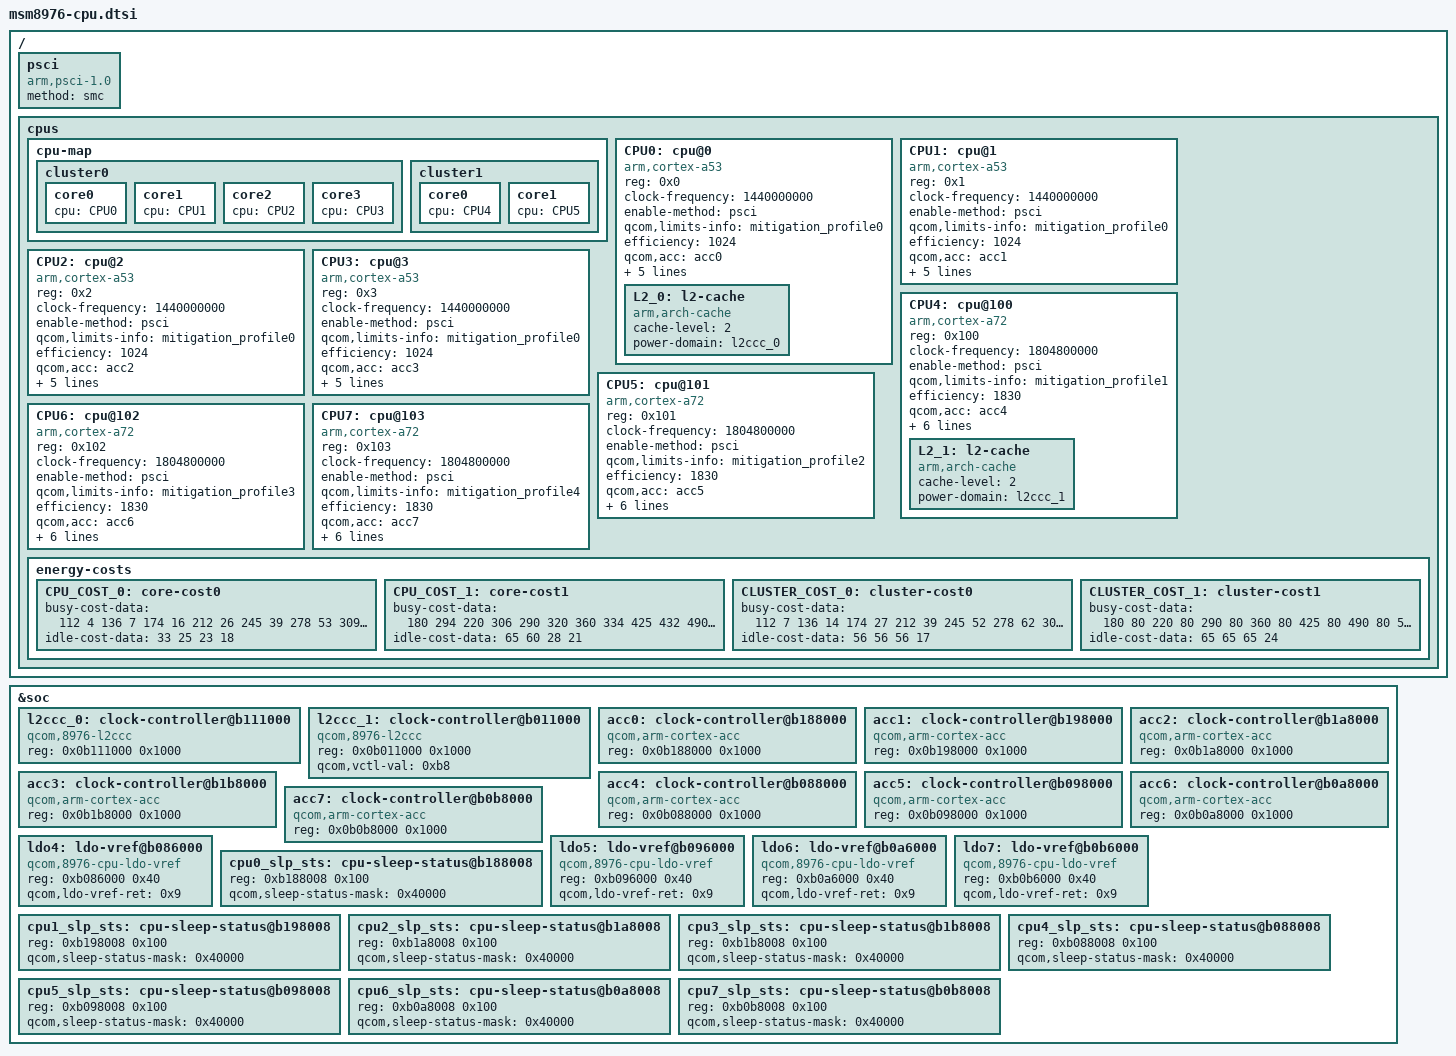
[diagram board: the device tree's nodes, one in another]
/* Copyright (c) 2015, The Linux Foundation. All rights reserved.
 *
 * This program is free software; you can redistribute it and/or modify
 * it under the terms of the GNU General Public License version 2 and
 * only version 2 as published by the Free Software Foundation.
 *
 * This program is distributed in the hope that it will be useful,
 * but WITHOUT ANY WARRANTY; without even the implied warranty of
 * MERCHANTABILITY or FITNESS FOR A PARTICULAR PURPOSE.  See the
 * GNU General Public License for more details.
 */


/ {

	psci {
		compatible = "arm,psci-1.0";
		method = "smc";
	};

	cpus {
		#address-cells = <1>;
		#size-cells = <0>;
		cpu-map {
			cluster0 {
				core0 {
					cpu = <&CPU0>;
				};
				core1 {
					cpu = <&CPU1>;
				};
				core2 {
					cpu = <&CPU2>;
				};
				core3 {
					cpu = <&CPU3>;
				};
			};

			cluster1 {
				core0 {
					cpu = <&CPU4>;
				};
				core1 {
					cpu = <&CPU5>;
				};
			};
		};

		CPU0: cpu@0 {
			device_type = "cpu";
			compatible = "arm,cortex-a53","arm,armv8";
			reg = <0x0>;
			clock-frequency = <1440000000>;
			enable-method = "psci";
			qcom,limits-info = <&mitigation_profile0>;
			efficiency = <1024>;
			qcom,acc = <&acc0>;
			next-level-cache = <&L2_0>;
			sched-energy-costs = <&CPU_COST_0 &CLUSTER_COST_0>;
			// The currents(uA) correspond to the frequencies in the
			// frequency table.
			current = < 18250 // 	 400000 kHZ
			            24330 // 	 691200 kHZ
			            26920 // 	 806400 kHZ
			            34600 //	1017600 kHz
			            38150 //	1190400 kHZ
			            46880 //	1305600 kHZ
			            55940 //	1382400 kHZ
			            81740 //	1401600 kHZ
			            105870>; //	1440000 kHZ
			qcom,sleep-status = <&cpu0_slp_sts>;
			L2_0: l2-cache {
			      compatible = "arm,arch-cache";
			      cache-level = <2>;
			      power-domain = <&l2ccc_0>;
			};
		};

		CPU1: cpu@1 {
			device_type = "cpu";
			compatible = "arm,cortex-a53","arm,armv8";
			reg = <0x1>;
			clock-frequency = <1440000000>;
			enable-method = "psci";
			qcom,limits-info = <&mitigation_profile0>;
			efficiency = <1024>;
			qcom,acc = <&acc1>;
			next-level-cache = <&L2_0>;
			sched-energy-costs = <&CPU_COST_0 &CLUSTER_COST_0>;
			// The currents(uA) correspond to the frequencies in the
			// frequency table.
			current = < 18250 // 	 400000 kHZ
			            24330 // 	 691200 kHZ
			            26920 // 	 806400 kHZ
			            34600 //	1017600 kHz
			            38150 //	1190400 kHZ
			            46880 //	1305600 kHZ
			            55940 //	1382400 kHZ
			            81740 //	1401600 kHZ
			            105870>; //	1440000 kHZ
			qcom,sleep-status = <&cpu1_slp_sts>;
		};

		CPU2: cpu@2 {
			device_type = "cpu";
			compatible = "arm,cortex-a53","arm,armv8";
			reg = <0x2>;
			clock-frequency = <1440000000>;
			enable-method = "psci";
			qcom,limits-info = <&mitigation_profile0>;
			efficiency = <1024>;
			qcom,acc = <&acc2>;
			next-level-cache = <&L2_0>;
			sched-energy-costs = <&CPU_COST_0 &CLUSTER_COST_0>;
			// The currents(uA) correspond to the frequencies in the
			// frequency table.
			current = < 18250 // 	 400000 kHZ
			            24330 // 	 691200 kHZ
			            26920 // 	 806400 kHZ
			            34600 //	1017600 kHz
			            38150 //	1190400 kHZ
			            46880 //	1305600 kHZ
			            55940 //	1382400 kHZ
			            81740 //	1401600 kHZ
			            105870>; //	1440000 kHZ
			qcom,sleep-status = <&cpu2_slp_sts>;
		};

		CPU3: cpu@3 {
			device_type = "cpu";
			compatible = "arm,cortex-a53","arm,armv8";
			reg = <0x3>;
			clock-frequency = <1440000000>;
			enable-method = "psci";
			qcom,limits-info = <&mitigation_profile0>;
			efficiency = <1024>;
			qcom,acc = <&acc3>;
			next-level-cache = <&L2_0>;
			sched-energy-costs = <&CPU_COST_0 &CLUSTER_COST_0>;
			// The currents(uA) correspond to the frequencies in the
			// frequency table.
			current = < 18250 // 	 400000 kHZ
			            24330 // 	 691200 kHZ
			            26920 // 	 806400 kHZ
			            34600 //	1017600 kHz
			            38150 //	1190400 kHZ
			            46880 //	1305600 kHZ
			            55940 //	1382400 kHZ
			            81740 //	1401600 kHZ
			            105870>; //	1440000 kHZ
			qcom,sleep-status = <&cpu3_slp_sts>;
		};

		CPU4: cpu@100 {
			device_type = "cpu";
			compatible = "arm,cortex-a72","arm,armv8";
			reg = <0x100>;
			clock-frequency = <1804800000>;
			enable-method = "psci";
			qcom,limits-info = <&mitigation_profile1>;
			efficiency = <1830>;
			qcom,acc = <&acc4>;
			qcom,ldo = <&ldo4>;
			next-level-cache = <&L2_1>;
			sched-energy-costs = <&CPU_COST_1 &CLUSTER_COST_1>;
			// The currents(uA) correspond to the frequencies in the
			// frequency table.
			current = < 67740 // 	 400000 kHZ
			            82960 // 	 883200 kHZ
			            105870 // 	 940800 kHZ
			            133160 // 	 998400 kHZ
			            150160 //	1056000 kHZ
			            167180 //	1113600 kHZ
			            230040 //	1190400 kHZ
			            261430 //	1248000 kHZ
			            290460 //	1305600 kHZ
			            317200 //	1382400 kHZ
			            352870 //	1612800 kHZ
			            374360 //	1747200 kHZ
			            443880>; //	1804800 kHZ
			qcom,sleep-status = <&cpu4_slp_sts>;
			L2_1: l2-cache {
			      compatible = "arm,arch-cache";
			      cache-level = <2>;
			      power-domain = <&l2ccc_1>;
			};
		};

		CPU5: cpu@101 {
			device_type = "cpu";
			compatible = "arm,cortex-a72","arm,armv8";
			reg = <0x101>;
			clock-frequency = <1804800000>;
			enable-method = "psci";
			qcom,limits-info = <&mitigation_profile2>;
			efficiency = <1830>;
			qcom,acc = <&acc5>;
			qcom,ldo = <&ldo5>;
			next-level-cache = <&L2_1>;
			sched-energy-costs = <&CPU_COST_1 &CLUSTER_COST_1>;
			// The currents(uA) correspond to the frequencies in the
			// frequency table.
			current = < 67740 // 	 400000 kHZ
			            82960 // 	 883200 kHZ
			            105870 // 	 940800 kHZ
			            133160 // 	 998400 kHZ
			            150160 //	1056000 kHZ
			            167180 //	1113600 kHZ
			            230040 //	1190400 kHZ
			            261430 //	1248000 kHZ
			            290460 //	1305600 kHZ
			            317200 //	1382400 kHZ
			            352870 //	1612800 kHZ
			            374360 //	1747200 kHZ
			            443880>; //	1804800 kHZ
			qcom,sleep-status = <&cpu5_slp_sts>;
		};

		CPU6: cpu@102 {
			device_type = "cpu";
			compatible = "arm,cortex-a72","arm,armv8";
			reg = <0x102>;
			clock-frequency = <1804800000>;
			enable-method = "psci";
			qcom,limits-info = <&mitigation_profile3>;
			efficiency = <1830>;
			qcom,acc = <&acc6>;
			qcom,ldo = <&ldo6>;
			next-level-cache = <&L2_1>;
			sched-energy-costs = <&CPU_COST_1 &CLUSTER_COST_1>;
			// The currents(uA) correspond to the frequencies in the
			// frequency table.
			current = < 67740 // 	 400000 kHZ
			            82960 // 	 883200 kHZ
			            105870 // 	 940800 kHZ
			            133160 // 	 998400 kHZ
			            150160 //	1056000 kHZ
			            167180 //	1113600 kHZ
			            230040 //	1190400 kHZ
			            261430 //	1248000 kHZ
			            290460 //	1305600 kHZ
			            317200 //	1382400 kHZ
			            352870 //	1612800 kHZ
			            374360 //	1747200 kHZ
			            443880>; //	1804800 kHZ
			qcom,sleep-status = <&cpu6_slp_sts>;
		};

		CPU7: cpu@103 {
			device_type = "cpu";
			compatible = "arm,cortex-a72","arm,armv8";
			reg = <0x103>;
			clock-frequency = <1804800000>;
			enable-method = "psci";
			qcom,limits-info = <&mitigation_profile4>;
			efficiency = <1830>;
			qcom,acc = <&acc7>;
			qcom,ldo = <&ldo7>;
			next-level-cache = <&L2_1>;
			sched-energy-costs = <&CPU_COST_1 &CLUSTER_COST_1>;
			// The currents(uA) correspond to the frequencies in the
			// frequency table.
			current = < 67740 // 	 400000 kHZ
			            82960 // 	 883200 kHZ
			            105870 // 	 940800 kHZ
			            133160 // 	 998400 kHZ
			            150160 //	1056000 kHZ
			            167180 //	1113600 kHZ
			            230040 //	1190400 kHZ
			            261430 //	1248000 kHZ
			            290460 //	1305600 kHZ
			            317200 //	1382400 kHZ
			            352870 //	1612800 kHZ
			            374360 //	1747200 kHZ
			            443880>; //	1804800 kHZ
			qcom,sleep-status = <&cpu7_slp_sts>;
		};

		energy-costs {
			CPU_COST_0: core-cost0 {
				busy-cost-data = <
					112     4
					136     7
					174    16
					212    26
					245    39
					278    53
					309    76
					339   102
					424   161
					509   227
				>;
				idle-cost-data = <
			  		33 25 23 18
				>;
			};
			CPU_COST_1: core-cost1 {
				busy-cost-data = <
					 180   294
					 220   306
					 290   320
					 360   334
					 425   432
					 490   533
					 599   721
					 708   917
 					 762  1058
 					 817  1203
					 871  1410
 					 926  1612
 					 975  1868
 					1024  2126
				>;
				idle-cost-data = <
			  		65 60 28 21
				>;
			};
			CLUSTER_COST_0: cluster-cost0 {
				busy-cost-data = <
					112    7
					136    14
					174    27
					212    39
					245    52
					278    62
					309    79
					339    94
					424   132
					509   165
				>;
				idle-cost-data = <
			 		56 56 56 17
				>;
			};
			CLUSTER_COST_1: cluster-cost1 {
				busy-cost-data = <
					 180   80
					 220   80
					 290   80
					 360   80
					 425   80
					 490   80
					 599   80
					 708   80
 					 762   80
 					 817   80
					 871   80
 					 926   80
 					 975   80
 					1024   80
				>;
				idle-cost-data = <
			 		65 65 65 24
				>;
			};
		};
		
	};
};

&soc {

	l2ccc_0: clock-controller@b111000 {
		compatible = "qcom,8976-l2ccc";
		reg = <0x0b111000 0x1000>;
		reg-names = "l2-base";
	};

	l2ccc_1: clock-controller@b011000 {
		compatible = "qcom,8976-l2ccc";
		reg = <0x0b011000 0x1000>;
		reg-names = "l2-base";
		qcom,vctl-val = <0xb8>;
	};

	acc0:clock-controller@b188000 {
		compatible = "qcom,arm-cortex-acc";
		reg = <0x0b188000 0x1000>;
	};

	acc1:clock-controller@b198000 {
		compatible = "qcom,arm-cortex-acc";
		reg = <0x0b198000 0x1000>;
	};

	acc2:clock-controller@b1a8000 {
		compatible = "qcom,arm-cortex-acc";
		reg = <0x0b1a8000 0x1000>;
	};

	acc3:clock-controller@b1b8000 {
		compatible = "qcom,arm-cortex-acc";
		reg = <0x0b1b8000 0x1000>;
	};

	acc4:clock-controller@b088000 {
		compatible = "qcom,arm-cortex-acc";
		reg = <0x0b088000 0x1000>;
	};

	acc5:clock-controller@b098000 {
		compatible = "qcom,arm-cortex-acc";
		reg = <0x0b098000 0x1000>;
	};

	acc6:clock-controller@b0a8000 {
		compatible = "qcom,arm-cortex-acc";
		reg = <0x0b0a8000 0x1000>;
	};

	acc7:clock-controller@b0b8000 {
		compatible = "qcom,arm-cortex-acc";
		reg = <0x0b0b8000 0x1000>;
	};

	ldo4:ldo-vref@b086000 {
		compatible = "qcom,8976-cpu-ldo-vref";
		reg = <0xb086000 0x40>;
		qcom,ldo-vref-ret = <0x9>;
	};

	ldo5:ldo-vref@b096000 {
		compatible = "qcom,8976-cpu-ldo-vref";
		reg = <0xb096000 0x40>;
		qcom,ldo-vref-ret = <0x9>;
	};

	ldo6:ldo-vref@b0a6000 {
		compatible = "qcom,8976-cpu-ldo-vref";
		reg = <0xb0a6000 0x40>;
		qcom,ldo-vref-ret = <0x9>;
	};

	ldo7:ldo-vref@b0b6000 {
		compatible = "qcom,8976-cpu-ldo-vref";
		reg = <0xb0b6000 0x40>;
		qcom,ldo-vref-ret = <0x9>;
	};

	cpu0_slp_sts: cpu-sleep-status@b188008 {
		reg = <0xb188008 0x100>;
		qcom,sleep-status-mask= <0x40000>;
	};

	cpu1_slp_sts: cpu-sleep-status@b198008 {
		reg = <0xb198008 0x100>;
		qcom,sleep-status-mask= <0x40000>;
	};

	cpu2_slp_sts: cpu-sleep-status@b1a8008 {
		reg = <0xb1a8008 0x100>;
		qcom,sleep-status-mask= <0x40000>;
	};

	cpu3_slp_sts: cpu-sleep-status@b1b8008 {
		reg = <0xb1b8008 0x100>;
		qcom,sleep-status-mask= <0x40000>;
	};

	cpu4_slp_sts: cpu-sleep-status@b088008 {
		reg = <0xb088008 0x100>;
		qcom,sleep-status-mask= <0x40000>;
	};

	cpu5_slp_sts: cpu-sleep-status@b098008 {
		reg = <0xb098008 0x100>;
		qcom,sleep-status-mask= <0x40000>;
	};

	cpu6_slp_sts: cpu-sleep-status@b0a8008 {
		reg = <0xb0a8008 0x100>;
		qcom,sleep-status-mask= <0x40000>;
	};

	cpu7_slp_sts: cpu-sleep-status@b0b8008 {
		reg = <0xb0b8008 0x100>;
		qcom,sleep-status-mask= <0x40000>;
	};

};
